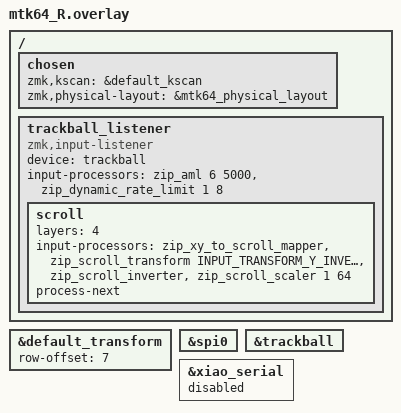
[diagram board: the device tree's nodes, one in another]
#include "mtk64.dtsi"
#include "mtk64_trackball.dtsi"
#include <dt-bindings/zmk/input_transform.h>

/ {
    chosen {
        zmk,kscan = &default_kscan;
        zmk,physical-layout = &mtk64_physical_layout;
    };
};

&default_transform {
    row-offset = <7>;
};

/*
&kscan0 {
    gpios
        = <&xiao_d 1 GPIO_ACTIVE_HIGH> 
        , <&xiao_d 2 GPIO_ACTIVE_HIGH> 
        , <&xiao_d 3 GPIO_ACTIVE_HIGH> 
        , <&xiao_d 6 GPIO_ACTIVE_HIGH>
        , <&xiao_d 7 GPIO_ACTIVE_HIGH> 
        , <&xiao_d 8 GPIO_ACTIVE_HIGH> 
        , <&xiao_d 9 GPIO_ACTIVE_HIGH> 	
    ;
};
*/

/ {
    trackball_listener: trackball_listener {
        compatible = "zmk,input-listener";
        status = "okay";
        device = <&trackball>;
        input-processors = <&zip_aml 6 5000>, <&zip_dynamic_rate_limit 1 8>;

        scroll {
            layers = <4>; // NumberPad (mtk64 Rev.1 フォーク設定)
            // 縦スクロールのみ反転 (Rev.1 フォークの旧 pmw3610 ドライバと同じ向き。横は rev3 標準のまま)
            input-processors = <&zip_xy_to_scroll_mapper>, <&zip_scroll_transform INPUT_TRANSFORM_Y_INVERT>, <&zip_scroll_inverter>, <&zip_scroll_scaler 1 64>;
            process-next;
        };
    };
};

&spi0 {
    status = "okay";
};

&trackball { 
    status = "okay";
};

&xiao_serial { status = "disabled"; };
